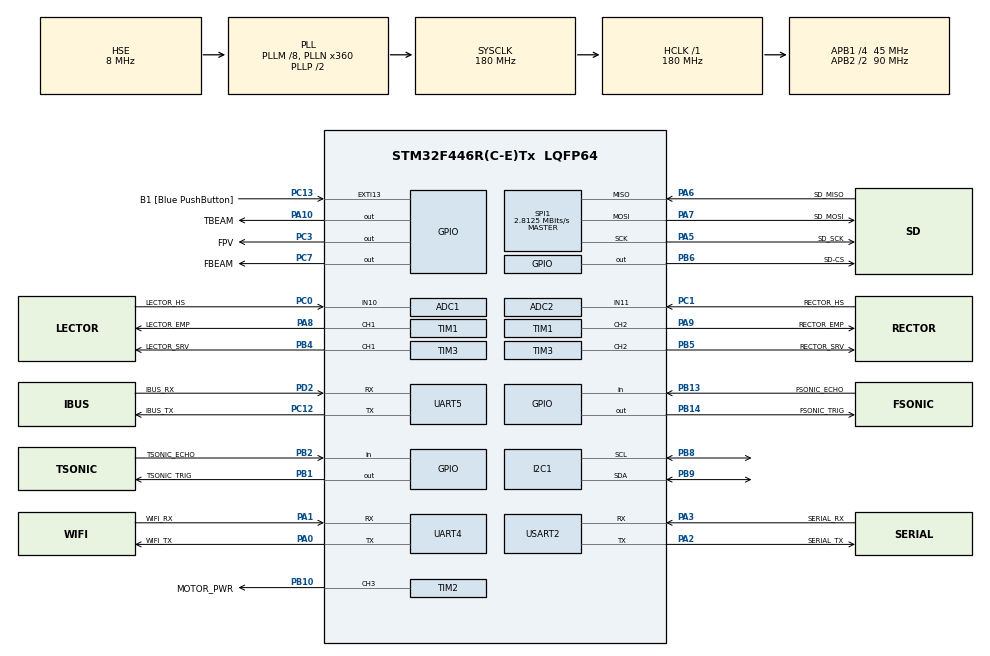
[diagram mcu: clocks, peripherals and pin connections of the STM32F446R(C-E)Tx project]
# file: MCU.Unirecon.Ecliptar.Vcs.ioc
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Dma.USART2_TX.7.MemInc=DMA_MINC_ENABLE
Dma.ADC3.8.Mode=DMA_CIRCULAR
Dma.USART2_TX.7.Priority=DMA_PRIORITY_LOW
PH0-OSC_IN.Signal=RCC_OSC_IN
Dma.USART2_TX.7.FIFOMode=DMA_FIFOMODE_DISABLE
SPI1.VirtualType=VM_MASTER
PB10.GPIO_PuPd=GPIO_NOPULL
ADC2.SamplingTime-1\#ChannelRegularConversion=ADC_SAMPLETIME_112CYCLES
Dma.UART5_TX.5.Priority=DMA_PRIORITY_LOW
PA10.GPIO_PuPd=GPIO_NOPULL
NVIC.DMA1_Stream2_IRQn=true\:0\:0\:false\:false\:true\:false\:true
PC12.Signal=UART5_TX
PB14.GPIO_Label=FSONIC_TRIG
PA14.GPIO_Label=TCK
Dma.USART2_RX.6.MemDataAlignment=DMA_MDATAALIGN_BYTE
VP_RTC_VS_RTC_Activate.Mode=RTC_Enabled
PA6.GPIO_Label=SD_MISO
PB6.GPIO_Label=SD-CS
Dma.UART5_TX.5.FIFOMode=DMA_FIFOMODE_DISABLE
PB13.Signal=GPIO_Input
RCC.SYSCLKSource=RCC_SYSCLKSOURCE_PLLCLK
Dma.USART2_RX.6.Direction=DMA_PERIPH_TO_MEMORY
Dma.UART5_RX.4.MemDataAlignment=DMA_MDATAALIGN_BYTE
SPI1.Direction=SPI_DIRECTION_2LINES
RCC.APB2TimFreq_Value=180000000
PB6.Signal=GPIO_Output
PC7.Signal=GPIO_Output
TIM1.AutomaticOutput=TIM_AUTOMATICOUTPUT_DISABLE
SPI1.CalculateBaudRate=2.8125 MBits/s
PC3.Signal=GPIO_Output
Dma.USART2_RX.6.Instance=DMA1_Stream5
ADC3.ScanConvMode=ENABLE
Dma.UART4_TX.1.FIFOMode=DMA_FIFOMODE_DISABLE
Dma.ADC2.3.MemDataAlignment=DMA_MDATAALIGN_HALFWORD
PB2.Signal=GPIO_Input
PB3.Mode=Trace_Asynchronous_SW
TIM1.LockLevel=TIM_LOCKLEVEL_OFF
PB10.GPIO_ModeDefaultPP=GPIO_MODE_AF_PP
Dma.ADC1.2.MemDataAlignment=DMA_MDATAALIGN_HALFWORD
TIM1.Channel-PWM\ Generation1\ CH1=TIM_CHANNEL_1
Dma.UART5_RX.4.Direction=DMA_PERIPH_TO_MEMORY
Dma.UART5_TX.5.Instance=DMA1_Stream7
PB1.GPIO_Label=TSONIC_TRIG
ADC3.ContinuousConvMode=ENABLE
Dma.ADC3.8.PeriphDataAlignment=DMA_PDATAALIGN_HALFWORD
Dma.ADC1.2.Direction=DMA_PERIPH_TO_MEMORY
PA8.Signal=S_TIM1_CH1
Dma.UART4_RX.0.PeriphDataAlignment=DMA_PDATAALIGN_BYTE
VP_TIM1_VS_ClockSourceINT.Mode=Internal
Mcu.Package=LQFP64
PB9.Signal=I2C1_SDA
PB1.Signal=GPIO_Output
PB14.GPIO_PuPd=GPIO_NOPULL
PB6.GPIO_ModeDefaultOutputPP=GPIO_MODE_OUTPUT_PP
ADC3.Rank-0\#ChannelRegularConversion=1
ADC2.Channel-1\#ChannelRegularConversion=ADC_CHANNEL_11
PA10.Signal=GPIO_Output
VP_RTC_VS_RTC_Calendar.Mode=RTC_Calendar
PB5.GPIO_Speed=GPIO_SPEED_FREQ_MEDIUM
Dma.USART2_TX.7.PeriphDataAlignment=DMA_PDATAALIGN_BYTE
ADC3.DMAContinuousRequests=ENABLE
RCC.APB2CLKDivider=RCC_HCLK_DIV2
NVIC.DMA2_Stream2_IRQn=true\:0\:0\:false\:false\:true\:false\:true
RCC.APB1TimFreq_Value=180000000
TIM3.Pulse-PWM\ Generation2\ CH2=3000
TIM1.Period=2047
NVIC.DMA1_Stream6_IRQn=true\:0\:0\:false\:false\:true\:false\:true
PA8.GPIO_Speed=GPIO_SPEED_FREQ_MEDIUM
Dma.USART2_TX.7.Instance=DMA1_Stream6
Dma.ADC1.2.Mode=DMA_CIRCULAR
NVIC.UART4_IRQn=true\:0\:0\:false\:false\:true\:true\:true
PA5.Mode=Full_Duplex_Master
Dma.UART4_RX.0.MemInc=DMA_MINC_ENABLE
Dma.ADC2.3.PeriphDataAlignment=DMA_PDATAALIGN_HALFWORD
TIM3.AutoReloadPreload=TIM_AUTORELOAD_PRELOAD_ENABLE
PC13.Signal=GPXTI13
PA9.GPIO_Label=RECTOR_EMP
PB6.GPIO_PuPd=GPIO_NOPULL
Dma.UART4_RX.0.Mode=DMA_CIRCULAR
NVIC.DMA2_Stream1_IRQn=true\:0\:0\:false\:false\:true\:false\:true
Dma.ADC2.3.Priority=DMA_PRIORITY_LOW
UART5.VirtualMode=Asynchronous
PC0.Signal=ADCx_IN10
Dma.UART5_RX.4.MemInc=DMA_MINC_ENABLE
RCC.APB1CLKDivider=RCC_HCLK_DIV4
UART4.VirtualMode=Asynchronous
PC14-OSC32_IN.Signal=RCC_OSC32_IN
Dma.USART2_RX.6.PeriphInc=DMA_PINC_DISABLE
PA0-WKUP.GPIO_Label=WIFI_TX
PA0-WKUP.Signal=UART4_TX
Dma.USART2_RX.6.FIFOMode=DMA_FIFOMODE_DISABLE
PA0-WKUP.Mode=Asynchronous
PA3.Mode=Asynchronous
Dma.USART2_RX.6.MemInc=DMA_MINC_ENABLE
TIM1.AutoReloadPreload=TIM_AUTORELOAD_PRELOAD_ENABLE
Dma.ADC1.2.MemInc=DMA_MINC_ENABLE
Dma.USART2_RX.6.Mode=DMA_CIRCULAR
PA8.GPIO_Label=LECTOR_EMP
TIM3.Pulse-PWM\ Generation1\ CH1=3000
ADC2.ContinuousConvMode=ENABLE
Dma.UART4_TX.1.Instance=DMA1_Stream4
PA9.Signal=S_TIM1_CH2
RCC.HSE_Timout=100
TIM1.Channel-PWM\ Generation2\ CH2=TIM_CHANNEL_2
PB4.GPIO_PuPd=GPIO_NOPULL
ADC3.NbrOfConversion=2
Dma.UART4_RX.0.PeriphInc=DMA_PINC_DISABLE
PB10.Signal=S_TIM2_CH3
PB14.Signal=GPIO_Output
Dma.ADC2.3.Direction=DMA_PERIPH_TO_MEMORY
PA5.Signal=SPI1_SCK
PC12.Mode=Asynchronous
Dma.UART4_RX.0.FIFOMode=DMA_FIFOMODE_DISABLE
PA1.Mode=Asynchronous
SPI1.CRCCalculation=SPI_CRCCALCULATION_DISABLE
PB4.GPIO_Label=LECTOR_SRV
SPI1.Mode=SPI_MODE_MASTER
PA1.GPIO_Label=WIFI_RX
RCC.RCC_RTC_Clock_SourceVirtual=RCC_RTCCLKSOURCE_LSE
Dma.USART2_TX.7.Direction=DMA_MEMORY_TO_PERIPH
ADC1.DMAContinuousRequests=ENABLE
TIM2.Period=2047
PA13.Mode=Trace_Asynchronous_SW
ADC3.Channel-1\#ChannelRegularConversion=ADC_CHANNEL_11
Dma.ADC1.2.Instance=DMA2_Stream0
PC7.GPIO_Label=FBEAM
ADC3.Rank-1\#ChannelRegularConversion=2
ADC1.SamplingTime-1\#ChannelRegularConversion=ADC_SAMPLETIME_112CYCLES
PB5.Signal=S_TIM3_CH2
ADC1.master=1
ADC2.NbrOfConversionFlag=1
PA5.GPIO_Label=SD_SCK
PB5.GPIO_PuPd=GPIO_NOPULL
Dma.UART5_RX.4.Priority=DMA_PRIORITY_LOW
PC12.GPIO_Label=IBUS_TX
ADC1.Rank-1\#ChannelRegularConversion=1
ProjectManager.HeapSize=0x200
ADC3.EOCSelection=ADC_EOC_SINGLE_CONV
Dma.ADC1.2.FIFOMode=DMA_FIFOMODE_DISABLE
Dma.USART2_TX.7.MemDataAlignment=DMA_MDATAALIGN_BYTE
NVIC.PriorityGroup=NVIC_PRIORITYGROUP_0
TIM3.Channel-PWM\ Generation2\ CH2=TIM_CHANNEL_2
PB8.Mode=I2C
Dma.UART4_RX.0.Instance=DMA1_Stream2
Dma.UART4_TX.1.MemDataAlignment=DMA_MDATAALIGN_BYTE
TIM2.AutoReloadPreload=TIM_AUTORELOAD_PRELOAD_ENABLE
PC3.GPIO_Label=FPV
PB1.GPIO_ModeDefaultOutputPP=GPIO_MODE_OUTPUT_PP
PD2.Signal=UART5_RX
PC1.Signal=ADCx_IN11
PD2.GPIO_Label=IBUS_RX
Dma.UART4_TX.1.Direction=DMA_MEMORY_TO_PERIPH
Mcu.Family=STM32F4
Dma.UART4_TX.1.PeriphDataAlignment=DMA_PDATAALIGN_BYTE
PA6.Mode=Full_Duplex_Master
RCC.CortexFreq_Value=180000000
PB10.GPIO_Speed=GPIO_SPEED_FREQ_MEDIUM
ADC1.ContinuousConvMode=ENABLE
PC0.GPIO_Label=LECTOR_HS
PC13.GPIO_Label=B1 [Blue PushButton]
PB13.GPIO_Label=FSONIC_ECHO
NVIC.DMA1_Stream4_IRQn=true\:0\:0\:false\:false\:true\:false\:true
ADC3.Channel-0\#ChannelRegularConversion=ADC_CHANNEL_10
ProjectManager.StackSize=0x400
NVIC.UART5_IRQn=true\:0\:0\:false\:false\:true\:true\:true
NVIC.ADC_IRQn=true\:0\:0\:false\:false\:true\:true\:true
ADC2.DMAContinuousRequests=ENABLE
Dma.USART2_TX.7.PeriphInc=DMA_PINC_DISABLE
PB1.GPIO_PuPd=GPIO_NOPULL
RCC.HCLKFreq_Value=180000000
TIM3.Period=39999
Dma.ADC2.3.PeriphInc=DMA_PINC_DISABLE
NVIC.DMA2_Stream0_IRQn=true\:0\:0\:false\:false\:true\:false\:true
RCC.AHBFreq_Value=180000000
PH0-OSC_IN.Mode=HSE-External-Oscillator
PB5.GPIO_ModeDefaultPP=GPIO_MODE_AF_PP
TIM3.Channel-PWM\ Generation1\ CH1=TIM_CHANNEL_1
ADC3.SamplingTime-1\#ChannelRegularConversion=ADC_SAMPLETIME_144CYCLES
RCC.HSE_VALUE=8000000
Dma.UART4_TX.1.Mode=DMA_NORMAL
Dma.UART4_RX.0.MemDataAlignment=DMA_MDATAALIGN_BYTE
PC14-OSC32_IN.Mode=LSE-External-Oscillator
Dma.UART5_TX.5.PeriphInc=DMA_PINC_DISABLE
PA14.Mode=Trace_Asynchronous_SW
TIM3.Prescaler=44
Dma.ADC3.8.MemInc=DMA_MINC_ENABLE
PA10.GPIO_Label=TBEAM
Dma.UART5_RX.4.Mode=DMA_CIRCULAR
SH.S_TIM3_CH1.0=TIM3_CH1,PWM Generation1 CH1
Dma.ADC3.8.Priority=DMA_PRIORITY_LOW
Dma.UART5_TX.5.MemInc=DMA_MINC_ENABLE
RCC.FLatency-AdvancedSettings=FLASH_LATENCY_5
NVIC.DMA1_Stream7_IRQn=true\:0\:0\:false\:false\:true\:false\:true
PH1-OSC_OUT.Mode=HSE-External-Oscillator
PA6.Signal=SPI1_MISO
Dma.ADC3.8.Direction=DMA_PERIPH_TO_MEMORY
USART2.VirtualMode=VM_ASYNC
Dma.ADC3.8.MemDataAlignment=DMA_MDATAALIGN_HALFWORD
Dma.UART4_TX.1.MemInc=DMA_MINC_ENABLE
PA2.GPIO_Label=SERIAL_TX
Dma.UART4_TX.1.PeriphInc=DMA_PINC_DISABLE
ADC3.ClockPrescaler=ADC_CLOCK_SYNC_PCLK_DIV6
PB5.GPIO_Label=RECTOR_SRV
TIM1.BreakState=TIM_BREAK_ENABLE
Dma.Request2=ADC1
Dma.Request1=UART4_TX
Dma.Request4=UART5_RX
Dma.Request3=ADC2
Dma.Request6=USART2_RX
Dma.Request5=UART5_TX
NVIC.DMA1_Stream0_IRQn=true\:0\:0\:false\:false\:true\:false\:true
Dma.Request8=ADC3
Dma.Request7=USART2_TX
Dma.Request0=UART4_RX
SPI1.BaudRatePrescaler=SPI_BAUDRATEPRESCALER_32
VP_TIM3_VS_ClockSourceINT.Mode=Internal
PB4.Signal=S_TIM3_CH1
PA3.Signal=USART2_RX
Dma.USART2_RX.6.PeriphDataAlignment=DMA_PDATAALIGN_BYTE
PB3.GPIO_Label=SWO
ADC2.ClockPrescaler=ADC_CLOCK_SYNC_PCLK_DIV6
RCC.PLLSourceVirtual=RCC_PLLSOURCE_HSE
PC15-OSC32_OUT.Mode=LSE-External-Oscillator
Dma.UART5_TX.5.Mode=DMA_NORMAL
TIM1.OffStateIDLEMode=TIM_OSSI_ENABLE
PA7.Mode=Full_Duplex_Master
Dma.UART5_TX.5.PeriphDataAlignment=DMA_PDATAALIGN_BYTE
Dma.ADC3.8.Instance=DMA2_Stream1
Dma.ADC1.2.PeriphDataAlignment=DMA_PDATAALIGN_HALFWORD
RCC.RCC_TIM_PRescaler_Selection=RCC_TIMPRES_ACTIVATED
Dma.UART5_TX.5.MemDataAlignment=DMA_MDATAALIGN_BYTE
Dma.ADC2.3.FIFOMode=DMA_FIFOMODE_DISABLE
Dma.ADC2.3.Instance=DMA2_Stream2
NVIC.USART2_IRQn=true\:0\:0\:false\:false\:true\:true\:true
PA13.Signal=SYS_JTMS-SWDIO
ADC3.SamplingTime-0\#ChannelRegularConversion=ADC_SAMPLETIME_144CYCLES
SH.S_TIM1_CH1.0=TIM1_CH1,PWM Generation1 CH1
Dma.UART4_RX.0.Direction=DMA_PERIPH_TO_MEMORY
Dma.ADC3.8.FIFOMode=DMA_FIFOMODE_DISABLE
ProjectManager.TargetToolchain=STM32CubeIDE
PB10.GPIO_Label=MOTOR_PWR
NVIC.DMA1_Stream5_IRQn=true\:0\:0\:false\:false\:true\:false\:true
PA10.GPIO_ModeDefaultOutputPP=GPIO_MODE_OUTPUT_PP
PB9.Mode=I2C
ADC1.Channel-1\#ChannelRegularConversion=ADC_CHANNEL_10
RCC.USBFreq_Value=180000000
PC15-OSC32_OUT.Signal=RCC_OSC32_OUT
PB14.GPIO_ModeDefaultOutputPP=GPIO_MODE_OUTPUT_PP
Dma.USART2_TX.7.Mode=DMA_NORMAL
PA1.Signal=UART4_RX
Dma.UART5_RX.4.PeriphInc=DMA_PINC_DISABLE
PD2.Mode=Asynchronous
SH.S_TIM3_CH2.0=TIM3_CH2,PWM Generation2 CH2
PB4.GPIO_ModeDefaultPP=GPIO_MODE_AF_PP
board=NUCLEO-F446RE
RCC.VCOOutputFreq_Value=360000000
Dma.UART4_RX.0.Priority=DMA_PRIORITY_LOW
PB4.GPIO_Speed=GPIO_SPEED_FREQ_MEDIUM
RCC.APB2Freq_Value=90000000
SH.ADCx_IN11.1=ADC3_IN11,IN11
SH.ADCx_IN11.0=ADC2_IN11,IN11
SH.S_TIM1_CH2.0=TIM1_CH2,PWM Generation2 CH2
VP_TIM2_VS_ClockSourceINT.Mode=Internal
SH.S_TIM2_CH3.0=TIM2_CH3,PWM Generation3 CH3
Dma.ADC2.3.Mode=DMA_CIRCULAR
PC1.GPIO_Label=RECTOR_HS
TIM2.Channel-PWM\ Generation3\ CH3=TIM_CHANNEL_3
PH1-OSC_OUT.Signal=RCC_OSC_OUT
Dma.UART5_RX.4.Instance=DMA1_Stream0
TIM1.OffStateRunMode=TIM_OSSR_DISABLE
Dma.ADC3.8.PeriphInc=DMA_PINC_DISABLE
Dma.ADC2.3.MemInc=DMA_MINC_ENABLE
TIM1.BreakPolarity=TIM_BREAKPOLARITY_LOW
Mcu.Name=STM32F446R(C-E)Tx
PA13.GPIO_Label=TMS
PA2.Signal=USART2_TX
RCC.48MHZClocksFreq_Value=84000000
PB3.Signal=SYS_JTDO-SWO
RCC.SYSCLKFreq_VALUE=180000000
Dma.ADC1.2.Priority=DMA_PRIORITY_LOW
Dma.UART5_RX.4.PeriphDataAlignment=DMA_PDATAALIGN_BYTE
PA7.GPIO_Label=SD_MOSI
Dma.ADC1.2.PeriphInc=DMA_PINC_DISABLE
PC13.GPIO_ModeDefaultEXTI=GPIO_MODE_IT_FALLING
Dma.UART5_RX.4.FIFOMode=DMA_FIFOMODE_DISABLE
SH.ADCx_IN10.1=ADC3_IN10,IN10
PA14.Signal=SYS_JTCK-SWCLK
SH.ADCx_IN10.0=ADC1_IN10,IN10
PB2.GPIO_Label=TSONIC_ECHO
Dma.UART4_TX.1.Priority=DMA_PRIORITY_LOW
RCC.HSI_VALUE=16000000
Dma.USART2_RX.6.Priority=DMA_PRIORITY_LOW
ADC1.NbrOfConversionFlag=1
RCC.PLLM=8
RCC.PLLN=360
ADC2.Rank-1\#ChannelRegularConversion=1
PA2.Mode=Asynchronous
PA9.GPIO_Speed=GPIO_SPEED_FREQ_MEDIUM
PB8.Signal=I2C1_SCL
RCC.APB1Freq_Value=45000000
ADC3.NbrOfConversionFlag=1
VP_CRC_VS_CRC.Mode=CRC_Activate
ADC1.ClockPrescaler=ADC_CLOCK_SYNC_PCLK_DIV6
Dma.UART5_TX.5.Direction=DMA_MEMORY_TO_PERIPH
PA3.GPIO_Label=SERIAL_RX
PA7.Signal=SPI1_MOSI

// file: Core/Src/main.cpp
/* USER CODE BEGIN Header */
/**
  ******************************************************************************
  * @file           : main.c
  * @brief          : Main program body
  ******************************************************************************
  * @attention
  *
  * <h2><center>&copy; Copyright (c) 2021 STMicroelectronics.
  * All rights reserved.</center></h2>
  *
  * This software component is licensed by ST under BSD 3-Clause license,
  * the "License"; You may not use this file except in compliance with the
  * License. You may obtain a copy of the License at:
  *                        opensource.org/licenses/BSD-3-Clause
  *
  ******************************************************************************
  */
/* USER CODE END Header */
#include "main.h"
#include "adc.h"
#include "crc.h"
#include "dma.h"
#include "i2c.h"
#include "rtc.h"
#include "spi.h"
#include "tim.h"
#include "usart.h"
#include "gpio.h"

/* USER CODE BEGIN Includes */
#include "config.h"
/* USER CODE END Includes */

/* USER CODE BEGIN PV */
//RC_IBUS* rc = &RC;
/* USER CODE END PV */

void SystemClock_Config(void);

int main(void)
{

  /* MCU Configuration--------------------------------------------------------*/

  /* Reset of all peripherals, Initializes the Flash interface and the Systick. */
  HAL_Init();

  /* Configure the system clock */
  SystemClock_Config();

  /* Initialize all configured peripherals */
  MX_GPIO_Init();
  MX_DMA_Init();
  MX_USART2_UART_Init();
  MX_SPI1_Init();
  MX_TIM1_Init();
  MX_TIM2_Init();
  MX_TIM3_Init();
  MX_UART5_Init();
  MX_I2C1_Init();
  MX_CRC_Init();
  MX_UART4_Init();
  MX_ADC1_Init();
  MX_ADC2_Init();
  MX_RTC_Init();
  MX_ADC3_Init();
  /* USER CODE BEGIN 2 */

  SerialUSB_Config();
  DriveSystem_Config();
  RemoteController_Config();

  /* USER CODE END 2 */

  /* Infinite loop */
  while (1)
  {

    /* USER CODE BEGIN 3 */

	RC.PrintInfoReport(RC.ReadChannels());

	Drive.PrintMeasureReport();

  }
  /* USER CODE END 3 */
}

void SystemClock_Config(void)
{
  RCC_OscInitTypeDef RCC_OscInitStruct = {0};
  RCC_ClkInitTypeDef RCC_ClkInitStruct = {0};
  RCC_PeriphCLKInitTypeDef PeriphClkInitStruct = {0};

  /** Configure the main internal regulator output voltage
  */
  __HAL_RCC_PWR_CLK_ENABLE();
  __HAL_PWR_VOLTAGESCALING_CONFIG(PWR_REGULATOR_VOLTAGE_SCALE1);
  /** Initializes the RCC Oscillators according to the specified parameters
  * in the RCC_OscInitTypeDef structure.
  */
  RCC_OscInitStruct.OscillatorType = RCC_OSCILLATORTYPE_HSE|RCC_OSCILLATORTYPE_LSE;
  RCC_OscInitStruct.HSEState = RCC_HSE_ON;
  RCC_OscInitStruct.LSEState = RCC_LSE_ON;
  RCC_OscInitStruct.PLL.PLLState = RCC_PLL_ON;
  RCC_OscInitStruct.PLL.PLLSource = RCC_PLLSOURCE_HSE;
  RCC_OscInitStruct.PLL.PLLM = 8;
  RCC_OscInitStruct.PLL.PLLN = 360;
  RCC_OscInitStruct.PLL.PLLP = RCC_PLLP_DIV2;
  RCC_OscInitStruct.PLL.PLLQ = 2;
  RCC_OscInitStruct.PLL.PLLR = 2;
  if (HAL_RCC_OscConfig(&RCC_OscInitStruct) != HAL_OK)
  {
    Error_Handler();
  }
  /** Activate the Over-Drive mode
  */
  if (HAL_PWREx_EnableOverDrive() != HAL_OK)
  {
    Error_Handler();
  }
  /** Initializes the CPU, AHB and APB buses clocks
  */
  RCC_ClkInitStruct.ClockType = RCC_CLOCKTYPE_HCLK|RCC_CLOCKTYPE_SYSCLK
                              |RCC_CLOCKTYPE_PCLK1|RCC_CLOCKTYPE_PCLK2;
  RCC_ClkInitStruct.SYSCLKSource = RCC_SYSCLKSOURCE_PLLCLK;
  RCC_ClkInitStruct.AHBCLKDivider = RCC_SYSCLK_DIV1;
  RCC_ClkInitStruct.APB1CLKDivider = RCC_HCLK_DIV4;
  RCC_ClkInitStruct.APB2CLKDivider = RCC_HCLK_DIV2;

  if (HAL_RCC_ClockConfig(&RCC_ClkInitStruct, FLASH_LATENCY_5) != HAL_OK)
  {
    Error_Handler();
  }
  PeriphClkInitStruct.PeriphClockSelection = RCC_PERIPHCLK_TIM|RCC_PERIPHCLK_RTC;
  PeriphClkInitStruct.RTCClockSelection = RCC_RTCCLKSOURCE_LSE;
  PeriphClkInitStruct.TIMPresSelection = RCC_TIMPRES_ACTIVATED;
  if (HAL_RCCEx_PeriphCLKConfig(&PeriphClkInitStruct) != HAL_OK)
  {
    Error_Handler();
  }
}

void Error_Handler(void)
{
  __disable_irq();
  while (1)
  {
  }
}

/************************ (C) COPYRIGHT STMicroelectronics *****END OF FILE****/
